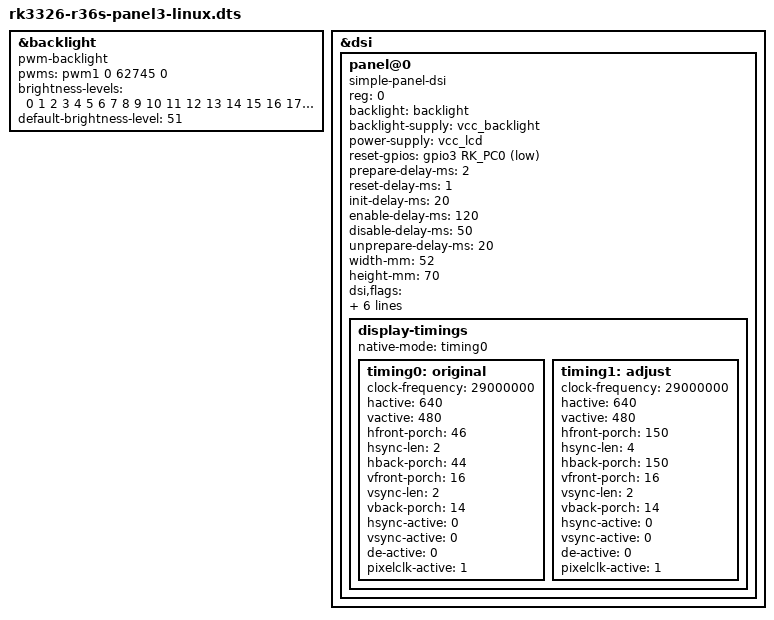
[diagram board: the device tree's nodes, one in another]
// SPDX-License-Identifier: (GPL-2.0+ OR MIT)
/*
* Copyright (c) 2026 kk&lcdyk
*
* GameConsole R36S
*
*/

/dts-v1/;
#include "rk3326-r36s-panel0-linux.dts"

&backlight {
	compatible = "pwm-backlight";
	pwms = <&pwm1 0 62745 0>;
	brightness-levels = <
	0   1   2   3   4   5   6   7
	8   9  10  11  12  13  14  15
	16  17  18  19  20  21  22  23
	24  25  26  27  28  29  30  31
	32  33  34  35  36  37  38  39
	40  41  42  43  44  45  46  47
	48  49  50  51  52  53  54  55
	56  57  58  59  60  61  62  63
	64  65  66  67  68  69  70  71
	72  73  74  75  76  77  78  79
	80  81  82  83  84  85  86  87
	88  89  90  91  92  93  94  95
	96  97  98  99 100 101 102 103
	104 105 106 107 108 109 110 111
	112 113 114 115 116 117 118 119
	120 121 122 123 124 125 126 127
	128 129 130 131 132 133 134 135
	136 137 138 139 140 141 142 143
	144 145 146 147 148 149 150 151
	152 153 154 155 156 157 158 159
	160>;
	default-brightness-level = <51>;
};

&dsi {
	status = "okay";
	
	panel@0 {
		compatible = "simple-panel-dsi";
		reg = <0>;
		/* pwm1 backlight */
		backlight = <&backlight>;
		/* RK817 LDO7 */
		backlight-supply = <&vcc_backlight>;
		/* RK817 LDO8 */
		power-supply = <&vcc_lcd>;
		/* Rev 0.2 LCD reset gpio GPIO3.C0 */
		reset-gpios = <&gpio3 RK_PC0 GPIO_ACTIVE_LOW>;
		prepare-delay-ms = <2>;
		reset-delay-ms = <1>;
		init-delay-ms = <20>;
		enable-delay-ms = <120>;
		disable-delay-ms = <50>;
		unprepare-delay-ms = <20>;
		width-mm = <52>;
		height-mm = <70>;
		dsi,flags  = <(MIPI_DSI_MODE_VIDEO |
		MIPI_DSI_MODE_VIDEO_BURST |
		MIPI_DSI_MODE_LPM |
		MIPI_DSI_MODE_EOT_PACKET)>;
		dsi,format = <MIPI_DSI_FMT_RGB888>;
		dsi,lanes = <4>;
		panel-init-sequence = [15 00 02 ff 30 15 00 02 ff 52 15 00 02 ff 01 15 00 02 e3 00 15 00 02 04 00 15 00 02 05 03 15 00 02 24 12 15 00 02 25 1e 15 00 02 26 6f 15 00 02 27 52 15 00 02 28 67 15 00 02 29 01 15 00 02 2a df 15 00 02 37 9c 15 00 02 38 a7 15 00 02 39 53 15 00 02 44 00 15 00 02 49 3c 15 00 02 59 fe 15 00 02 5c 00 15 00 02 80 20 15 00 02 91 77 15 00 02 92 77 15 00 02 a0 55 15 00 02 a1 50 15 00 02 a4 9c 15 00 02 a7 02 15 00 02 a8 01 15 00 02 a9 21 15 00 02 aa fc 15 00 02 ab 28 15 00 02 ac 06 15 00 02 ad 06 15 00 02 ae 06 15 00 02 af 03 15 00 02 b0 08 15 00 02 b1 26 15 00 02 b2 28 15 00 02 b3 28 15 00 02 b4 33 15 00 02 b5 08 15 00 02 b6 26 15 00 02 b7 08 15 00 02 b8 26 15 00 02 c0 00 15 00 02 c1 00 15 00 02 c2 00 15 00 02 ff 30 15 00 02 ff 52 15 00 02 ff 02 15 00 02 b0 0b 15 00 02 b1 16 15 00 02 b2 17 15 00 02 b3 2c 15 00 02 b4 32 15 00 02 b5 3b 15 00 02 b6 29 15 00 02 b7 40 15 00 02 b8 0d 15 00 02 b9 05 15 00 02 ba 12 15 00 02 bb 10 15 00 02 bc 12 15 00 02 bd 15 15 00 02 be 19 15 00 02 bf 0e 15 00 02 c0 16 15 00 02 c1 0a 15 00 02 d0 0c 15 00 02 d1 17 15 00 02 d2 14 15 00 02 d3 2e 15 00 02 d4 32 15 00 02 d5 3c 15 00 02 d6 22 15 00 02 d7 3d 15 00 02 d8 0d 15 00 02 d9 07 15 00 02 da 13 15 00 02 db 13 15 00 02 dc 11 15 00 02 dd 15 15 00 02 de 19 15 00 02 df 10 15 00 02 e0 17 15 00 02 e1 0a 15 00 02 ff 30 15 00 02 ff 52 15 00 02 ff 03 15 00 02 00 2a 15 00 02 01 2a 15 00 02 02 2a 15 00 02 03 2a 15 00 02 04 61 15 00 02 05 80 15 00 02 06 c7 15 00 02 07 01 15 00 02 08 82 15 00 02 09 83 15 00 02 30 2a 15 00 02 31 2a 15 00 02 32 2a 15 00 02 33 2a 15 00 02 34 a1 15 00 02 35 c5 15 00 02 36 80 15 00 02 37 23 15 00 02 40 82 15 00 02 41 83 15 00 02 42 80 15 00 02 43 81 15 00 02 44 55 15 00 02 45 e6 15 00 02 46 e5 15 00 02 47 55 15 00 02 48 e8 15 00 02 49 e7 15 00 02 50 02 15 00 02 51 01 15 00 02 52 04 15 00 02 53 03 15 00 02 54 55 15 00 02 55 ea 15 00 02 56 e9 15 00 02 57 55 15 00 02 58 ec 15 00 02 59 eb 15 00 02 7e 02 15 00 02 7f 80 15 00 02 e0 5a 15 00 02 b1 00 15 00 02 b4 0e 15 00 02 b5 0f 15 00 02 b6 04 15 00 02 b7 07 15 00 02 b8 06 15 00 02 b9 05 15 00 02 ba 0f 15 00 02 c7 00 15 00 02 ca 0e 15 00 02 cb 0f 15 00 02 cc 04 15 00 02 cd 07 15 00 02 ce 06 15 00 02 cf 05 15 00 02 d0 0f 15 00 02 81 0f 15 00 02 84 0e 15 00 02 85 0f 15 00 02 86 07 15 00 02 87 04 15 00 02 88 05 15 00 02 89 06 15 00 02 8a 00 15 00 02 97 0f 15 00 02 9a 0e 15 00 02 9b 0f 15 00 02 9c 07 15 00 02 9d 04 15 00 02 9e 05 15 00 02 9f 06 15 00 02 a0 00 15 00 02 ff 30 15 00 02 ff 52 15 00 02 ff 02 15 00 02 01 01 15 00 02 02 da 15 00 02 03 ba 15 00 02 04 a8 15 00 02 05 9a 15 00 02 06 70 15 00 02 07 ff 15 00 02 08 91 15 00 02 09 90 15 00 02 0a ff 15 00 02 0b 8f 15 00 02 0c 60 15 00 02 0d 58 15 00 02 0e 48 15 00 02 0f 38 15 00 02 10 2b 15 00 02 ff 30 15 00 02 ff 52 15 00 02 ff 00 15 00 02 36 02 15 00 02 3a 70 05 c8 01 11 05 14 01 29];
		panel-exit-sequence = <0x5140128 0x50a0110>;
		
		
		display-timings {
			native-mode = <&timing0>;
			
			// 29.00MHz / (640+46+2+44)×(480+16+2+14) = 732×512 = 77.38 Hz
			timing0: original {
				clock-frequency = <29000000>;
				hactive = <640>;
				vactive = <480>;
				hfront-porch = <46>;
				hsync-len = <2>;
				hback-porch = <44>;
				vfront-porch = <16>;
				vsync-len = <2>;
				vback-porch = <14>;
				hsync-active = <0>;
				vsync-active = <0>;
				de-active = <0>;
				pixelclk-active = <1>;
			};
			
			// 29.00MHz / (640+150+4+150)×(480+16+2+14) = 944×512 = 60.00 Hz
			timing1: adjust {
				clock-frequency = <29000000>;
				hactive = <640>;
				vactive = <480>;
				hfront-porch = <150>;
				hsync-len = <4>;
				hback-porch = <150>;
				vfront-porch = <16>;
				vsync-len = <2>;
				vback-porch = <14>;
				hsync-active = <0>;
				vsync-active = <0>;
				de-active = <0>;
				pixelclk-active = <1>;
			};
		};
	};
};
